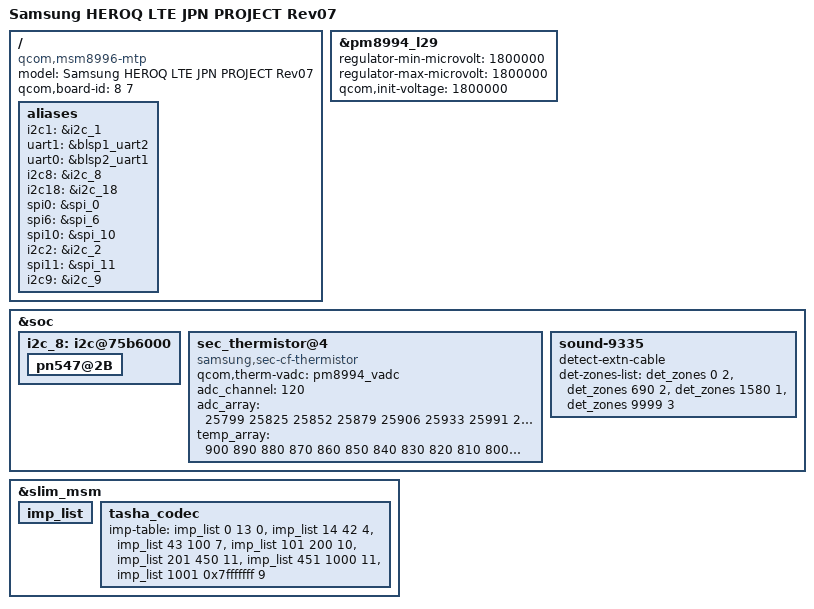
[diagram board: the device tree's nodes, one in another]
/* Copyright (c) 2015, The Linux Foundation. All rights reserved.
 *
 * This program is free software; you can redistribute it and/or modify
 * it under the terms of the GNU General Public License version 2 and
 * only version 2 as published by the Free Software Foundation.
 *
 * This program is distributed in the hope that it will be useful,
 * but WITHOUT ANY WARRANTY; without even the implied warranty of
 * MERCHANTABILITY or FITNESS FOR A PARTICULAR PURPOSE.  See the
 * GNU General Public License for more details.
 */

/dts-v1/;

#include "../qcom/msm8996-v3.dtsi"
#include "../qcom/msm8996-pm8994-pm8004.dtsi"
#include "../qcom/msm8996-mtp.dtsi"
#include "msm8996-max77838.dtsi"
#include "msm8996-s2mpb02-hero.dtsi"
#include "msm8996-sec-common.dtsi"
#include "msm8996-sec-heroqlte-common.dtsi"
#include "msm8996-sec-heroqlte-r07.dtsi"
#include "msm8996-sec-heroq_jpn-isdbt-00.dtsi"
#include "msm8996-heroqlte-nfc-jpn.dtsi"
/ {
	model = "Samsung HEROQ LTE JPN PROJECT Rev07";
	compatible = "qcom,msm8996-mtp", "qcom,msm8996", "qcom,mtp";
	qcom,board-id = <8 7>;

	aliases {
//		i2c3 = &i2c_3;
		i2c1 = &i2c_1;
		uart1 = &blsp1_uart2;
		uart0 = &blsp2_uart1;
		i2c8 = &i2c_8;
		i2c18 = &i2c_18;
		spi0 = &spi_0;
		spi6 = &spi_6;
		spi10 = &spi_10;
		i2c2 = &i2c_2;
		spi11 = &spi_11;
		i2c9 = &i2c_9;
	};
};

/***************************************************/
/* <<< JPN model specific overriding configuration */

&pm8994_l29 {
	regulator-min-microvolt = <1800000>;
	regulator-max-microvolt = <1800000>;
	qcom,init-voltage = <1800000>;
	/delete-property/ regulator-always-on;
};
&soc {
	/* Delete FM radio configuration. It's not used in JPN project */
	/delete-node/ i2c@64;
	/* Delete NFC clock configuration. BBCLK2 is used for ISDBT */
	i2c_8: i2c@75b6000 { /* BLSP2 QUP1 */
		pn547@2B {
			/delete-property/ clocks;
			/delete-property/ clocks-names;
			/delete-property/ qcom,clk-src;
		};
	};

	sec_thermistor@4 {
		compatible = "samsung,sec-cf-thermistor";
		qcom,therm-vadc = <&pm8994_vadc>;
		status = "okay";
		adc_channel = <120>;
		adc_array = <25799 25825 25852 25879 25906 25933 25991 26050
				  	 26109 26168 26227 26264 26301 26338 26375 26413
				  	 26492 26571 26651 26730 26810 26882 26954 27026
				  	 27098 27170 27256 27343 27430 27517 27604 27700
				  	 27797 27893 27990 28087 28229 28371 28513 28655
				  	 28797 28856 28915 28975 29034 29094 29301 29508
				  	 29715 29922 30130 30325 30520 30715 30910 31105
				  	 31353 31602 31851 32100 32349 32491 32633 32776
				  	 32918 33061 33246 33431 33616 33801 33986 34214
				  	 34443 34672 34901 35130 35395 35660 35926 36191
				  	 36457 36671 36885 37099 37313 37528 37734 37941
				  	 38148 38355 38562 38741 38920 39099 39278 39457
				  	 39585 39714 39842 39971 40100 40213 40327 40441
				  	 40555 40669 40714 40759 40805 40850 40896 >;

		temp_array = <900 890 880 870 860 850 840 830 820 810
			800 790 780 770 760 750 740 730 720 710
			700 690 680 670 660 650 640 630 620 610
			600 590 580 570 560 550 540 530 520 510
			500 490 480 470 460 450 440 430 420 410
			400 390 380 370 360 350 340 330 320 310
			300 290 280 270 260 250 240 230 220 210
			200 190 180 170 160 150 140 130 120 110
			100 90 80 70 60 50 40 30 20 10
			0 (-10) (-20) (-30) (-40) (-50) (-60) (-70) (-80) (-90)
			(-100)(-110)(-120)(-130)(-140)(-150)(-160)(-170)(-180)(-190)
			(-200)>;
	};

	sound-9335 {
		detect-extn-cable;
		det-zones-list = <&det_zones 0 2>,
				 <&det_zones 690 2>,
				 <&det_zones 1580 1>,
				 <&det_zones 9999 3>;
	};
};

&slim_msm {
	imp_list: imp_list {
		#list-imp-cells = <3>;
	};

	tasha_codec {
		imp-table = <&imp_list 0 13 0>,
				 <&imp_list 14 42 4>,
				 <&imp_list 43 100 7>,
				 <&imp_list 101 200 10>,
				 <&imp_list 201 450 11>,
				 <&imp_list 451 1000 11>,
				 <&imp_list 1001 0x7fffffff 9>;
	};
};

/* JPN model specific overriding configuration >>> */
/***************************************************/
